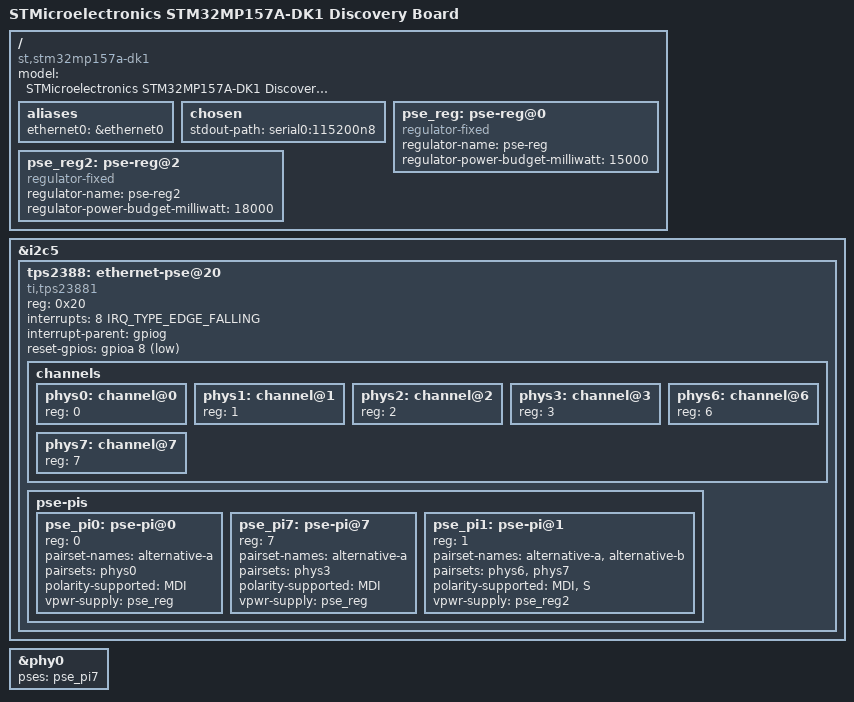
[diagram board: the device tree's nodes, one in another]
// SPDX-License-Identifier: (GPL-2.0+ OR BSD-3-Clause)
/*
 * Copyright (C) STMicroelectronics 2019 - All Rights Reserved
 * Author: Alexandre Torgue <alexandre.torgue@st.com> for STMicroelectronics.
 */

/dts-v1/;

#include "stm32mp157.dtsi"
#include "stm32mp15-pinctrl.dtsi"
#include "stm32mp15xxac-pinctrl.dtsi"
#include "stm32mp15xx-dkx.dtsi"

/ {
	model = "STMicroelectronics STM32MP157A-DK1 Discovery Board";
	compatible = "st,stm32mp157a-dk1", "st,stm32mp157";

	aliases {
		ethernet0 = &ethernet0;
	};

	chosen {
		stdout-path = "serial0:115200n8";
	};

	pse_reg: pse-reg@0 {
		compatible = "regulator-fixed";
		regulator-name = "pse-reg";
		regulator-power-budget-milliwatt = <15000>;
	};

	pse_reg2: pse-reg@2 {
		compatible = "regulator-fixed";
		regulator-name = "pse-reg2";
		regulator-power-budget-milliwatt = <18000>;
	};
};

&i2c5 {
	status = "okay";

	tps2388:ethernet-pse@20 {
		compatible = "ti,tps23881";
		reg = <0x20>;
		interrupts = <8 IRQ_TYPE_EDGE_FALLING>;
		interrupt-parent = <&gpiog>;
		reset-gpios = <&gpioa 8 GPIO_ACTIVE_LOW>;
		channels {
			#address-cells = <1>;
			#size-cells = <0>;

			phys0: channel@0 {
				reg = <0>;
			};

			phys1: channel@1 {
				reg = <1>;
			};

			phys2: channel@2 {
				reg = <2>;
			};

			phys3: channel@3 {
				reg = <3>;
			};

			phys6: channel@6 {
				reg = <6>;
			};

			phys7: channel@7 {
				reg = <7>;
			};
		};

		pse-pis {
			#address-cells = <1>;
			#size-cells = <0>;

			pse_pi0: pse-pi@0 {
				reg = <0>;
				#pse-cells = <0>;
				pairset-names = "alternative-a";
				pairsets = <&phys0>;
				polarity-supported = "MDI";
				vpwr-supply = <&pse_reg>;
			};

			pse_pi7: pse-pi@7 {
				reg = <7>;
				#pse-cells = <0>;
				pairset-names = "alternative-a";
				pairsets = <&phys3>;
				polarity-supported = "MDI";
				vpwr-supply = <&pse_reg>;
			};

			pse_pi1: pse-pi@1 {
				reg = <1>;
				#pse-cells = <0>;
				pairset-names = "alternative-a", "alternative-b";
				pairsets = <&phys6 &phys7>;
				polarity-supported = "MDI", "S";
				vpwr-supply = <&pse_reg2>;
			};
		};
	};
};

&phy0 {
	pses = <&pse_pi7>;
};
